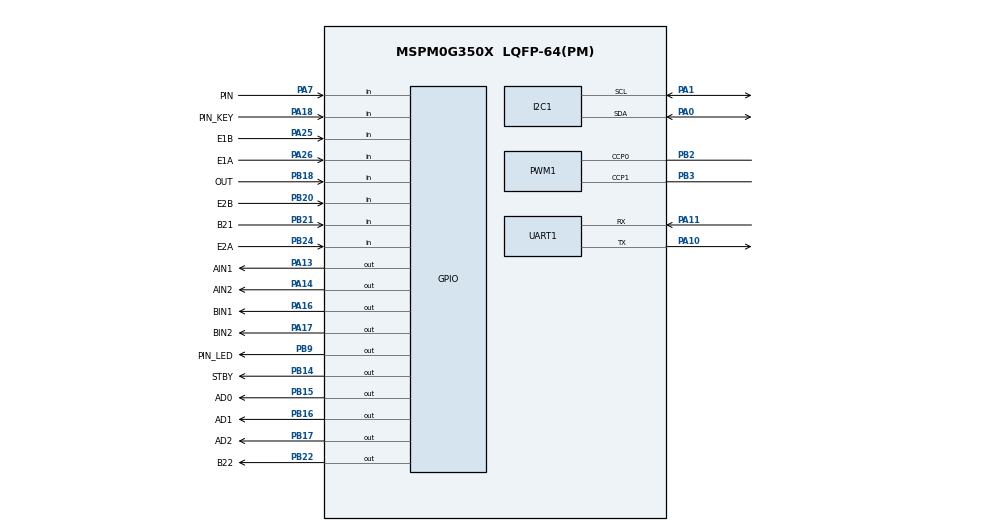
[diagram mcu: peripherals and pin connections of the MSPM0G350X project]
/**
 * @cliArgs --device "MSPM0G350X" --part "Default" --package "LQFP-64(PM)" --product "mspm0_sdk@2.05.00.05"
 * @versions {"tool":"1.24.0+4150"}
 */

/**
 * Import the modules used in this configuration.
 */
const GPIO   = scripting.addModule("/ti/driverlib/GPIO", {}, false);
const GPIO1  = GPIO.addInstance();
const GPIO2  = GPIO.addInstance();
const GPIO3  = GPIO.addInstance();
const GPIO4  = GPIO.addInstance();
const GPIO5  = GPIO.addInstance();
const GPIO6  = GPIO.addInstance();
const GPIO7  = GPIO.addInstance();
const GPIO8  = GPIO.addInstance();
const GPIO9  = GPIO.addInstance();
const GPIO10 = GPIO.addInstance();
const GPIO11 = GPIO.addInstance();
const I2C    = scripting.addModule("/ti/driverlib/I2C", {}, false);
const I2C1   = I2C.addInstance();
const PWM    = scripting.addModule("/ti/driverlib/PWM", {}, false);
const PWM1   = PWM.addInstance();
const SYSCTL = scripting.addModule("/ti/driverlib/SYSCTL");
const TIMER  = scripting.addModule("/ti/driverlib/TIMER", {}, false);
const TIMER2 = TIMER.addInstance();
const UART   = scripting.addModule("/ti/driverlib/UART", {}, false);
const UART1  = UART.addInstance();

/**
 * Write custom configuration values to the imported modules.
 */
const gate7  = system.clockTree["MFCLKGATE"];
gate7.enable = true;

GPIO1.$name                               = "KEY";
GPIO1.port                                = "PORTB";
GPIO1.associatedPins[0].$name             = "B21";
GPIO1.associatedPins[0].direction         = "INPUT";
GPIO1.associatedPins[0].ioStructure       = "SD";
GPIO1.associatedPins[0].internalResistor  = "PULL_UP";
GPIO1.associatedPins[0].assignedPin       = "21";
GPIO1.associatedPins[0].polarity          = "RISE";
GPIO1.associatedPins[0].interruptPriority = "3";
GPIO1.associatedPins[0].pin.$assign       = "PB21";

const Board = scripting.addModule("/ti/driverlib/Board", {}, false);

GPIO2.$name                              = "LED";
GPIO2.port                               = "PORTB";
GPIO2.associatedPins[0].$name            = "B22";
GPIO2.associatedPins[0].ioStructure      = "SD";
GPIO2.associatedPins[0].internalResistor = "PULL_DOWN";
GPIO2.associatedPins[0].assignedPin      = "22";
GPIO2.associatedPins[0].pin.$assign      = "PB22";

GPIO3.$name                         = "CAR_KEY";
GPIO3.associatedPins[0].$name       = "PIN_KEY";
GPIO3.associatedPins[0].direction   = "INPUT";
GPIO3.associatedPins[0].pin.$assign = "PA18";

GPIO4.$name                         = "CAR_LED";
GPIO4.associatedPins[0].$name       = "PIN_LED";
GPIO4.associatedPins[0].pin.$assign = "PB9";

GPIO5.port                          = "PORTA";
GPIO5.$name                         = "BIN";
GPIO5.associatedPins.create(2);
GPIO5.associatedPins[0].$name       = "BIN1";
GPIO5.associatedPins[0].pin.$assign = "PA16";
GPIO5.associatedPins[1].$name       = "BIN2";
GPIO5.associatedPins[1].pin.$assign = "PA17";

GPIO6.port                          = "PORTA";
GPIO6.$name                         = "AIN";
GPIO6.associatedPins.create(2);
GPIO6.associatedPins[0].$name       = "AIN1";
GPIO6.associatedPins[0].pin.$assign = "PA13";
GPIO6.associatedPins[1].$name       = "AIN2";
GPIO6.associatedPins[1].pin.$assign = "PA14";

GPIO7.$name                               = "ENCODERA";
GPIO7.associatedPins.create(2);
GPIO7.associatedPins[0].$name             = "E1A";
GPIO7.associatedPins[0].direction         = "INPUT";
GPIO7.associatedPins[0].pin.$assign       = "PA26";
GPIO7.associatedPins[1].$name             = "E1B";
GPIO7.associatedPins[1].direction         = "INPUT";
GPIO7.associatedPins[1].pin.$assign       = "PA25";

GPIO8.$name                               = "ENCODERB";
GPIO8.associatedPins.create(2);
GPIO8.associatedPins[0].$name             = "E2A";
GPIO8.associatedPins[0].direction         = "INPUT";
GPIO8.associatedPins[0].pin.$assign       = "PB24";
GPIO8.associatedPins[1].$name             = "E2B";
GPIO8.associatedPins[1].direction         = "INPUT";
GPIO8.associatedPins[1].pin.$assign       = "PB20";

GPIO9.$name                         = "EIGHT_IR";
GPIO9.associatedPins.create(4);
GPIO9.associatedPins[0].$name       = "AD0";
GPIO9.associatedPins[0].pin.$assign = "PB15";
GPIO9.associatedPins[1].$name       = "AD1";
GPIO9.associatedPins[1].pin.$assign = "PB16";
GPIO9.associatedPins[2].$name       = "AD2";
GPIO9.associatedPins[2].pin.$assign = "PB17";
GPIO9.associatedPins[3].$name       = "OUT";
GPIO9.associatedPins[3].direction   = "INPUT";
GPIO9.associatedPins[3].pin.$assign = "PB18";

GPIO10.$name                              = "MOTOR_STBY";
GPIO10.port                               = "PORTB";
GPIO10.associatedPins[0].$name            = "STBY";
GPIO10.associatedPins[0].initialValue     = "CLEARED";
GPIO10.associatedPins[0].pin.$assign      = "PB14";

GPIO11.$name                               = "MPU6050_INT";
GPIO11.associatedPins[0].$name             = "PIN";
GPIO11.associatedPins[0].direction         = "INPUT";
GPIO11.associatedPins[0].internalResistor  = "PULL_UP";
GPIO11.associatedPins[0].polarity          = "FALL";
GPIO11.associatedPins[0].interruptPriority = "2";
GPIO11.associatedPins[0].interruptEn       = true;
GPIO11.associatedPins[0].pin.$assign       = "PA7";

I2C1.$name                           = "I2C_0";
I2C1.basicEnableController           = true;
I2C1.basicControllerStandardBusSpeed = "Fast";
I2C1.peripheral.$assign              = "I2C0";
I2C1.peripheral.sdaPin.$assign       = "PA0";
I2C1.peripheral.sclPin.$assign       = "PA1";
I2C1.sdaPinConfig.$name              = "ti_driverlib_gpio_GPIOPinGeneric2";
I2C1.sclPinConfig.$name              = "ti_driverlib_gpio_GPIOPinGeneric3";

SYSCTL.forceDefaultClkConfig = true;
SYSCTL.clockTreeEn           = true;
scripting.suppress("For best practices when the CPUCLK is running at 32MHz and above, clear the flash status bit using DL_FlashCTL_executeClearStatus\\(\\) before executing any flash operation\\. Otherwise there may be false positives\\.", SYSCTL);

PWM1.$name                      = "PWM_0";
PWM1.timerStartTimer            = true;
PWM1.pwmMode                    = "EDGE_ALIGN_UP";
PWM1.timerCount                 = 3200;
PWM1.peripheral.$assign         = "TIMA1";
PWM1.peripheral.ccp0Pin.$assign = "PB2";
PWM1.peripheral.ccp1Pin.$assign = "PB3";
PWM1.PWM_CHANNEL_0.$name        = "ti_driverlib_pwm_PWMTimerCC0";
PWM1.PWM_CHANNEL_1.$name        = "ti_driverlib_pwm_PWMTimerCC1";
PWM1.ccp0PinConfig.$name        = "ti_driverlib_gpio_GPIOPinGeneric4";
PWM1.ccp1PinConfig.$name        = "ti_driverlib_gpio_GPIOPinGeneric5";

TIMER2.$name              = "TIM_delay_ms";
TIMER2.timerClkDiv        = 1;
TIMER2.timerClkPrescale   = 4;
TIMER2.timerClkSrc        = "MFCLK";
TIMER2.timerPeriod        = "1 ms";
TIMER2.peripheral.$assign = "TIMA0";

UART1.enabledInterrupts                = ["RX"];
UART1.interruptPriority                = "3";
UART1.$name                            = "UART_DEBUG";
UART1.targetBaudRate                   = 115200;
UART1.peripheral.$assign               = "UART0";
UART1.peripheral.rxPin.$assign         = "PA11";
UART1.peripheral.txPin.$assign         = "PA10";
UART1.txPinConfig.$name                = "ti_driverlib_gpio_GPIOPinGeneric0";
UART1.txPinConfig.direction            = scripting.forceWrite("OUTPUT");
UART1.txPinConfig.hideOutputInversion  = scripting.forceWrite(false);
UART1.txPinConfig.onlyInternalResistor = scripting.forceWrite(false);
UART1.txPinConfig.passedPeripheralType = scripting.forceWrite("Digital");
UART1.rxPinConfig.$name                = "ti_driverlib_gpio_GPIOPinGeneric1";
UART1.rxPinConfig.hideOutputInversion  = scripting.forceWrite(false);
UART1.rxPinConfig.onlyInternalResistor = scripting.forceWrite(false);
UART1.rxPinConfig.passedPeripheralType = scripting.forceWrite("Digital");

/**
 * Pinmux solution for unlocked pins/peripherals. This ensures that minor changes to the automatic solver in a future
 * version of the tool will not impact the pinmux you originally saw.  These lines can be completely deleted in order to
 * re-solve from scratch.
 */
Board.peripheral.$suggestSolution                  = "DEBUGSS";
Board.peripheral.swclkPin.$suggestSolution         = "PA20";
Board.peripheral.swdioPin.$suggestSolution         = "PA19";
